AUTOSAR XML (schema 00052)
package /katech/AdaptiveApplicationSwComponentTypes
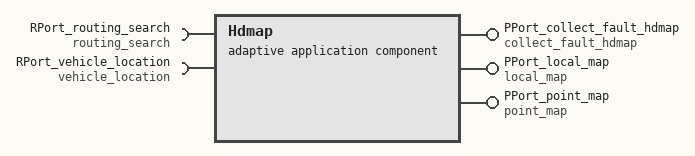
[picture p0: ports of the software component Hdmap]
  adaptive application sw component type Hdmap
    provide port PPort_collect_fault_hdmap: provided-interface=collect_fault_hdmap
    provide port PPort_local_map: provided-interface=local_map
    provide port PPort_point_map: provided-interface=point_map
    require port RPort_routing_search: required-interface=routing_search
    require port RPort_vehicle_location: required-interface=vehicle_location
package /katech/Executables
  executable Hdmap: category=APPLICATION_LEVEL, minimum-timer-granularity=1000
    root sw component prototype Hdmap: application-type=Hdmap
